# STM32H523 register map
File version: 1.2
CPU: CM33 r0p0, little endian, MPU, FPU, 4 interrupt priority bits
Registers are 32-bit, read-write, reset 0x0 unless marked. A register's access mark holds for its fields unless they carry their own. Offsets are from the block's base; [hi:lo] are bit positions; lines under a group give offsets from that group; {n}, {i} and the like mark numbered series; 'fields as' and 'values as' point back to an identical list.

## FLASH — Mustang_FLASH register block
Base 0x40022000
Same registers: FLASH_S 0x50022000
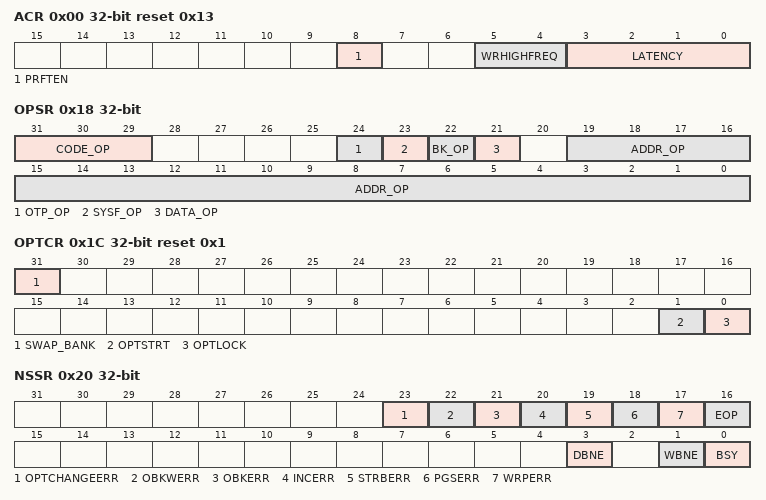
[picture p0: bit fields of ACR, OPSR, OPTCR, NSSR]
0x00 ACR reset 0x13 — FLASH access control register
  [8] PRFTEN — Prefetch enable.
  [5:4] WRHIGHFREQ — Flash signal delay
  [3:0] LATENCY — Read latency
0x04 NSKEYR wo — FLASH non-secure key register
  [31:0] NSKEY — Non-volatile memory non-secure configuration access unlock key
0x08 SECKEYR wo — FLASH secure key register
  [31:0] SECKEY — Non-volatile memory secure configuration access unlock key
0x0C OPTKEYR wo — FLASH option key register
  [31:0] OPTKEY — FLASH option bytes control access unlock key
0x10 NSOBKKEYR wo — FLASH non-secure OBK key register
  [31:0] NSOBKKEY — FLASH non-secure option bytes keys control access unlock key
0x14 SECOBKKEYR wo — FLASH secure OBK key register
  [31:0] SECOBKKEY — FLASH secure option bytes keys control access unlock key
0x18 OPSR ro reset not defined — FLASH operation status register
  [31:29] CODE_OP — Flash memory operation code
  [24] OTP_OP — OTP operation interrupted
  [23] SYSF_OP — Operation in system flash memory interrupted
  [22] BK_OP — Interrupted operation bank
  [21] DATA_OP — Flash high-cycle data area operation interrupted
  [19:0] ADDR_OP — Interrupted operation address
0x1C OPTCR reset 0x1 (reset mask 0xFFFFFFF) — FLASH option control register
  [31] SWAP_BANK ro — Bank swapping option configuration bit
  [1] OPTSTRT — Option byte start change option configuration bit
  [0] OPTLOCK — FLASH_OPTCR lock option configuration bit
0x20 NSSR ro (reset mask 0xFFFFFFF0) — FLASH non-secure status register
  [23] OPTCHANGEERR — Option byte change error flag
  [22] OBKWERR — OBK write error flag
  [21] OBKERR — OBK general error flag
  [20] INCERR — inconsistency error flag
  [19] STRBERR — strobe error flag
  [18] PGSERR — programming sequence error flag
  [17] WRPERR — write protection error flag
  [16] EOP — end of operation flag
  [3] DBNE — data buffer not empty flag
  [1] WBNE — write buffer not empty flag
  [0] BSY — busy flag
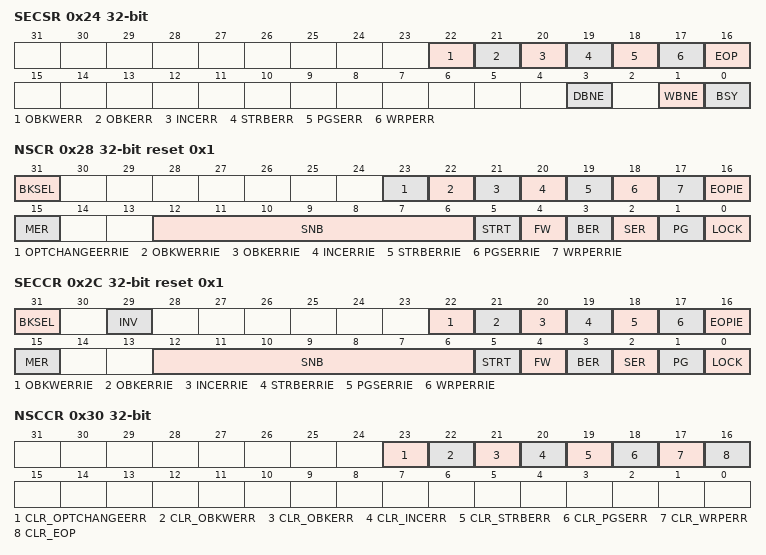
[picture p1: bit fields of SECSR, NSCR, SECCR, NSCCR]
0x24 SECSR ro (reset mask 0xFFFFFFF0) — FLASH secure status register
  [22] OBKWERR — OBK write error flag
  [21] OBKERR — OBK general error flag
  [20] INCERR — inconsistency error flag
  [19] STRBERR — strobe error flag
  [18] PGSERR — programming sequence error flag
  [17] WRPERR — write protection error flag
  [16] EOP — end of operation flag
  [3] DBNE — data buffer not empty flag
  [1] WBNE — write buffer not empty flag
  [0] BSY — busy flag
0x28 NSCR reset 0x1 — FLASH non-secure control register
  [31] BKSEL — Bank selector bit
  [23] OPTCHANGEERRIE — Option byte change error interrupt enable bit
  [22] OBKWERRIE — OBK write error interrupt enable bit
  [21] OBKERRIE — OBK general error interrupt enable bit
  [20] INCERRIE — inconsistency error interrupt enable bit
  [19] STRBERRIE — strobe error interrupt enable bit
  [18] PGSERRIE — programming sequence error interrupt enable bit
  [17] WRPERRIE — write protection error interrupt enable bit
  [16] EOPIE — end of operation interrupt control bit
  [15] MER — mass erase request
  [12:6] SNB — sector erase selection number
  [5] STRT — erase start control bit
  [4] FW — write forcing control bit
  [3] BER — erase request
  [2] SER — sector erase request
  [1] PG — programming control bit
  [0] LOCK — configuration lock bit
0x2C SECCR reset 0x1 — FLASH secure control register
  [31] BKSEL — Bank selector bit
  [29] INV — Flash memory security state invert.
  [22] OBKWERRIE — OBK write error interrupt enable bit
  [21] OBKERRIE — OBK general error interrupt enable bit
  [20] INCERRIE — inconsistency error interrupt enable bit
  [19] STRBERRIE — strobe error interrupt enable bit
  [18] PGSERRIE — programming sequence error interrupt enable bit
  [17] WRPERRIE — write protection error interrupt enable bit
  [16] EOPIE — end of operation interrupt control bit
  [15] MER — mass erase request
  [12:6] SNB — sector erase selection number
  [5] STRT — erase start control bit
  [4] FW — write forcing control bit
  [3] BER — erase request
  [2] SER — sector erase request
  [1] PG — programming control bit
  [0] LOCK — configuration lock bit
0x30 NSCCR wo — FLASH non-secure clear control register
  [23] CLR_OPTCHANGEERR — Clear the flag corresponding flag in FLASH_NSSR by writing this bit.
  [22] CLR_OBKWERR — OBKWERR flag clear bit.
  [21] CLR_OBKERR — OBKERR flag clear bit.
  [20] CLR_INCERR — INCERR flag clear bit
  [19] CLR_STRBERR — STRBERR flag clear bit
  [18] CLR_PGSERR — PGSERR flag clear bit
  [17] CLR_WRPERR — WRPERR flag clear bit
  [16] CLR_EOP — EOP flag clear bit
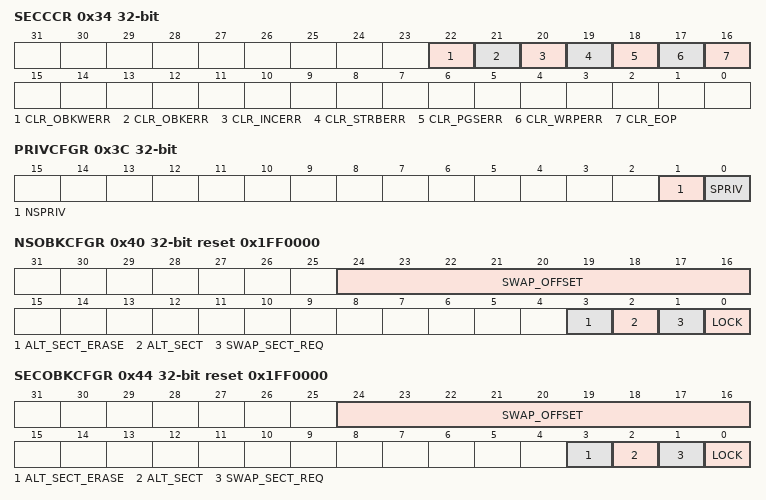
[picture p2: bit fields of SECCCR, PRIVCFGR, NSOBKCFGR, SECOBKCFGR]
0x34 SECCCR wo — FLASH secure clear control register
  [22] CLR_OBKWERR — OBKWERR flag clear bit
  [21] CLR_OBKERR — OBKWERR flag clear bit
  [20] CLR_INCERR — INCERR flag clear bit
  [19] CLR_STRBERR — STRBERR flag clear bit
  [18] CLR_PGSERR — PGSERR flag clear bit
  [17] CLR_WRPERR — WRPERR flag clear bit
  [16] CLR_EOP — EOP flag clear bit
0x3C PRIVCFGR — FLASH privilege configuration register
  [1] NSPRIV — privilege attribute for non secure registers
  [0] SPRIV — privilege attribute for secure registers
0x40 NSOBKCFGR reset 0x1FF0000 — FLASH non-secure OBK configuration register
  [24:16] SWAP_OFFSET — Key index (offset /16 bits) pointing for next swap.
  [3] ALT_SECT_ERASE — alternate sector erase bit
  [2] ALT_SECT — alternate sector bit
  [1] SWAP_SECT_REQ — OBK swap sector request bit
  [0] LOCK — OBKCFGR lock option configuration bit
0x44 SECOBKCFGR reset 0x1FF0000 — FLASH secure OBK configuration register
  [24:16] SWAP_OFFSET — key index (offset /16 bits) pointing for next swap.
  [3] ALT_SECT_ERASE — alternate sector erase bit
  [2] ALT_SECT — alternate sector bit
  [1] SWAP_SECT_REQ — OBK swap sector request bit
  [0] LOCK — OBKCFGR lock option configuration bit
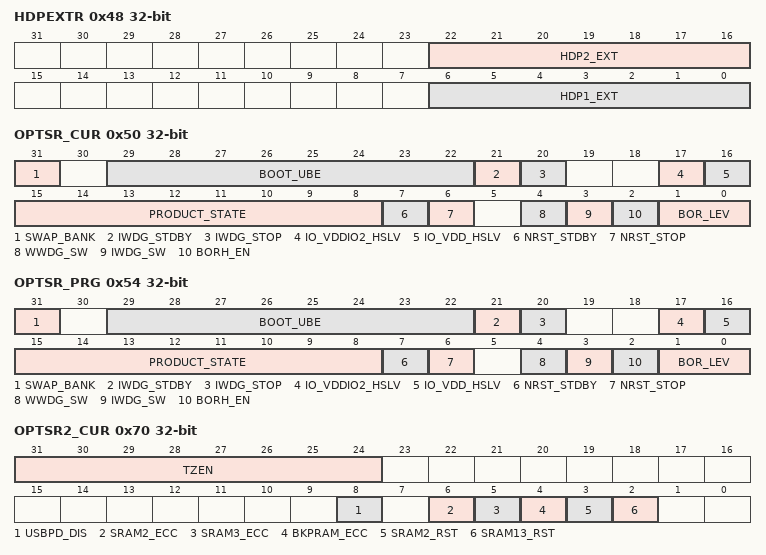
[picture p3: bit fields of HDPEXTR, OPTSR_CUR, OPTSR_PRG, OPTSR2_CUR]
0x48 HDPEXTR — FLASH HDP extension register
  [22:16] HDP2_EXT — HDP area extension in 8 Kbytes sectors in Bank2.
  [6:0] HDP1_EXT — HDP area extension in 8 Kbytes sectors in Bank1.
0x50 OPTSR_CUR ro reset not defined — FLASH option status register
  [31] SWAP_BANK — Bank swapping option status bit
  [29:22] BOOT_UBE — Available only on cryptography enabled devices.
  [21] IWDG_STDBY — IWDG Standby mode freeze option status bit
  [20] IWDG_STOP — IWDG Stop mode freeze option status bit
  [17] IO_VDDIO2_HSLV — High-speed IO at low Vless thansub>DDIO2less than/sub> voltage configuration bit.
  [16] IO_VDD_HSLV — High-speed IO at low Vless thansub>DDless than/sub> voltage configuration bit.
  [15:8] PRODUCT_STATE — Life state code (based on Hamming 8,4).
  [7] NRST_STDBY — Core domain Standby entry reset option status bit
  [6] NRST_STOP — Core domain Stop entry reset option status bit
  [4] WWDG_SW — WWDG control mode option status bit
  [3] IWDG_SW — IWDG control mode option status bit
  [2] BORH_EN — Brownout high enable
  [1:0] BOR_LEV — Brownout level option status bit
0x54 OPTSR_PRG reset not defined — FLASH option status register
  [31] SWAP_BANK — Bank swapping option configuration bit
  [29:22] BOOT_UBE — Available only on cryptography enabled devices.
  [21] IWDG_STDBY — IWDG Standby mode freeze option status bit
  [20] IWDG_STOP — IWDG Stop mode freeze option status bit
  [17] IO_VDDIO2_HSLV — High-speed IO at low Vless thansub>DDIO2less than/sub> voltage configuration bit.
  [16] IO_VDD_HSLV — High-speed IO at low VDD voltage configuration bit.
  [15:8] PRODUCT_STATE — Life state code (based on Hamming 8,4).
  [7] NRST_STDBY — Core domain Standby entry reset option configuration bit
  [6] NRST_STOP — Core domain Stop entry reset option configuration bit
  [4] WWDG_SW — WWDG control mode option configuration bit
  [3] IWDG_SW — IWDG control mode option configuration bit
  [2] BORH_EN — Brownout high enable configuration bit
  [1:0] BOR_LEV — Brownout level option configuration bit
0x60 NSEPOCHR_CUR ro reset not defined — FLASH non-secure EPOCH register
  [23:0] NS_EPOCH — Non-volatile non-secure EPOCH counter
0x68 SECEPOCHR_CUR ro reset not defined — FLASH secure EPOCH register
  [23:0] SEC_EPOCH — Non-volatile secure EPOCH counter
0x70 OPTSR2_CUR ro reset not defined — FLASH option status register 2
  [31:24] TZEN — TrustZone enable configuration bits
  [8] USBPD_DIS — USB power delivery configuration option bit
  [6] SRAM2_ECC — SRAM2 ECC detection and correction disable
  [5] SRAM3_ECC — SRAM3 ECC detection and correction disable
  [4] BKPRAM_ECC — Backup RAM ECC detection and correction disable
  [3] SRAM2_RST — SRAM2 erase when system reset
  [2] SRAM13_RST — SRAM1 and SRAM3 erase upon system reset
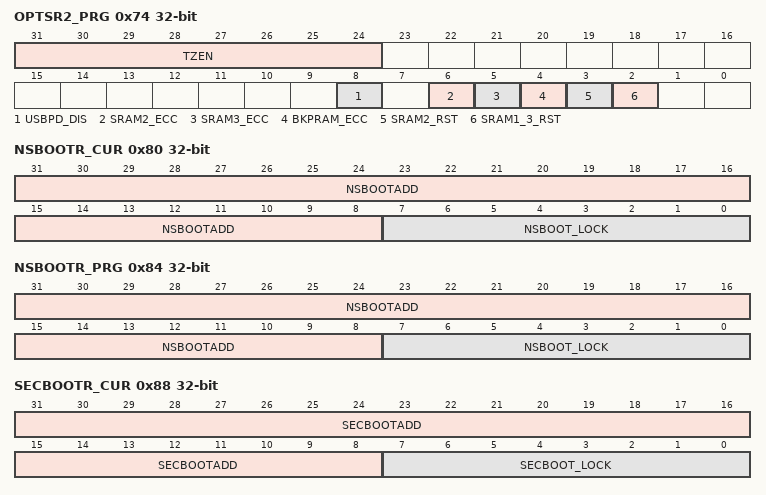
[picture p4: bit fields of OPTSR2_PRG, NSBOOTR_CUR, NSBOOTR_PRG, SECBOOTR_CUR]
0x74 OPTSR2_PRG reset not defined — FLASH option status register 2
  [31:24] TZEN — TrustZone enable configuration bits
  [8] USBPD_DIS — USB power delivery configuration option bit
  [6] SRAM2_ECC — SRAM2 ECC detection and correction disable
  [5] SRAM3_ECC — SRAM3 ECC detection and correction disable
  [4] BKPRAM_ECC — Backup RAM ECC detection and correction disable
  [3] SRAM2_RST — SRAM2 erase when system reset
  [2] SRAM1_3_RST — SRAM1 and SRAM3 erase upon system reset
0x80 NSBOOTR_CUR ro reset not defined — FLASH non-secure boot register
  [31:8] NSBOOTADD — Non secure unique boot entry address
  [7:0] NSBOOT_LOCK — Field locking the values of SWAP_BANK, and NSBOOTADD settings.
0x84 NSBOOTR_PRG reset not defined — FLASH non-secure boot register
  [31:8] NSBOOTADD — Non secure unique boot entry address
  [7:0] NSBOOT_LOCK — Field locking the values of SWAP_ BANK, and NSBOOTADD settings.
0x88 SECBOOTR_CUR ro reset not defined — FLASH secure boot register
  [31:8] SECBOOTADD — Unique boot entry secure address
  [7:0] SECBOOT_LOCK — Field locking the values of UBE, SWAP_BANK, and SECBOOTADD settings.
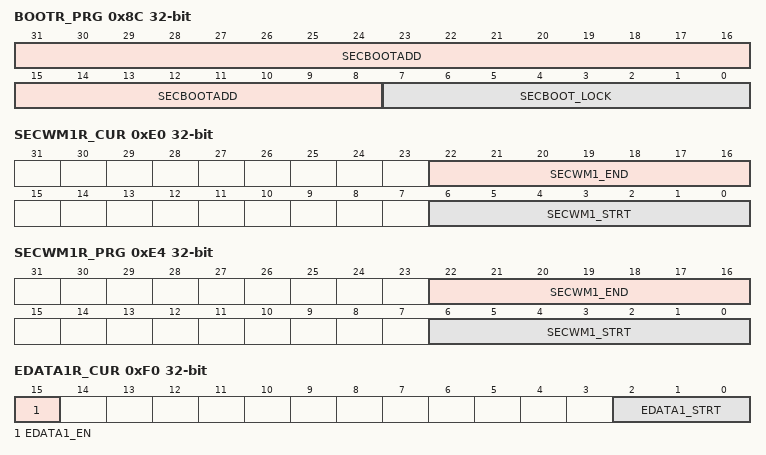
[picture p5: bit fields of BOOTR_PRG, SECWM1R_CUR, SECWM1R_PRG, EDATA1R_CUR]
0x8C BOOTR_PRG reset not defined — FLASH secure boot register
  [31:8] SECBOOTADD — Secure unique boot entry address.
  [7:0] SECBOOT_LOCK — Field locking the values of UBE, SWAP_ BANK, and SECBOOTADD setting.
0x90 OTPBLR_CUR ro reset not defined — FLASH non-secure OTP block lock
  [31:0] LOCKBL — OTP block lock
0x94 OTPBLR_PRG reset not defined — FLASH non-secure OTP block lock
  [31:0] LOCKBL — OTP block lock
{0x9C+4i} SECBB1R{i} (i=1..4) — FLASH secure block based register for Bank1
  [31:0] SECBB1 — Secure/non-secure 8 Kbytes flash Bank1 sector attributes
{0xBC+4i} PRIVBB1R{i} (i=1..4) — FLASH privilege block based register for Bank1
  [31:0] PRIVBB1 — Privileged/unprivileged 8-Kbyte flash Bank1 sector attribute
0xE0 SECWM1R_CUR ro (reset mask 0xFF00FF00) — FLASH security watermark for Bank1
  [22:16] SECWM1_END — Bank1 security WM area 1 end sector
  [6:0] SECWM1_STRT — Bank1 security WM area 1 start sector
0xE4 SECWM1R_PRG (reset mask 0xFF00FF00) — FLASH security watermark for Bank1
  fields as SECWM1R_CUR
0xE8 WRP1R_CUR ro reset not defined — FLASH write sector group protection for Bank1
  [31:0] WRPSG1 — Bank1 sector group protection option status byte
0xEC WRP1R_PRG reset not defined — FLASH write sector group protection for Bank1
  [31:0] WRPSG1 — Bank1 sector group protection option status byte
0xF0 EDATA1R_CUR ro reset not defined — FLASH data sector configuration Bank1
  [15] EDATA1_EN — Bank1 flash high-cycle data enable
  [2:0] EDATA1_STRT — EDATA1_STRT contains the start sectors of the flash high-cycle data area in Bank1 There is no hardware effect to those bits.
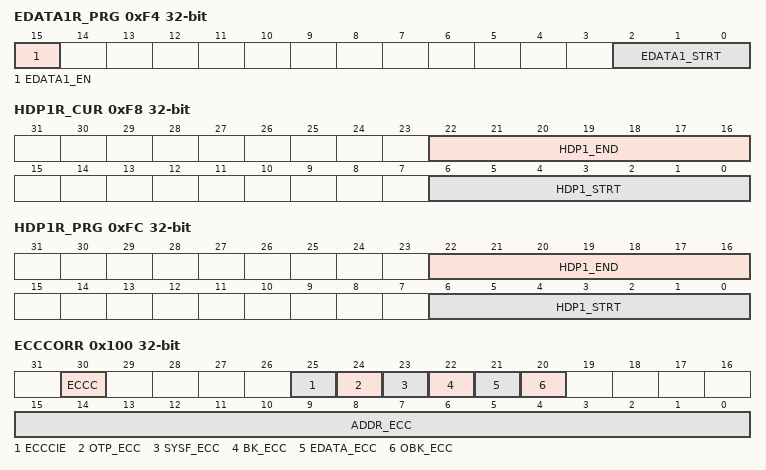
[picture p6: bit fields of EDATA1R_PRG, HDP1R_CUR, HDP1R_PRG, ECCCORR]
0xF4 EDATA1R_PRG reset not defined — FLASH data sector configuration Bank1
  fields as EDATA1R_CUR
0xF8 HDP1R_CUR ro reset not defined — FLASH HDP Bank1 configuration
  [22:16] HDP1_END — HDPL barrier end set in number of 8-Kbyte sectors
  [6:0] HDP1_STRT — HDPL barrier start set in number of 8-Kbyte sectors
0xFC HDP1R_PRG reset not defined — FLASH HDP Bank1 configuration
  fields as HDP1R_CUR
0x100 ECCCORR — FLASH ECC correction register
  [30] ECCC — ECC correction set by hardware when single ECC error has been detected and corrected.
  [25] ECCCIE — ECC single correction error interrupt enable bit
  [24] OTP_ECC ro — OTP ECC error bit
  [23] SYSF_ECC ro — ECC fail for corrected ECC error in system flash memory
  [22] BK_ECC ro — ECC fail bank for corrected ECC error
  [21] EDATA_ECC ro — ECC fail for corrected ECC error in flash high-cycle data area
  [20] OBK_ECC ro — Single ECC error corrected in flash OB Keys storage area.
  [15:0] ADDR_ECC ro — ECC error address
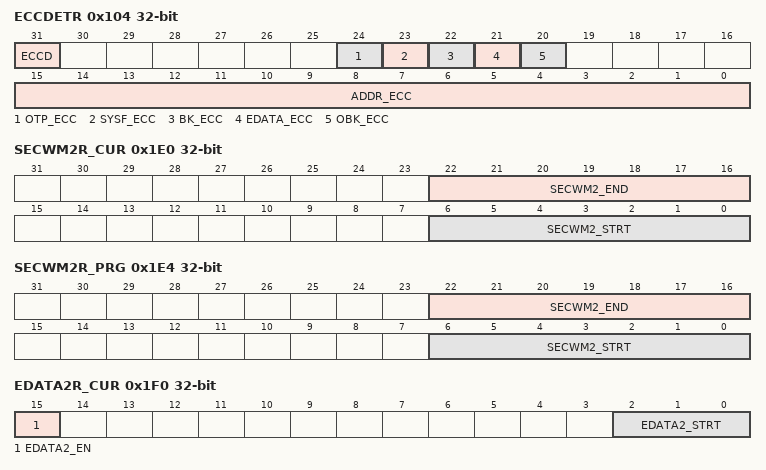
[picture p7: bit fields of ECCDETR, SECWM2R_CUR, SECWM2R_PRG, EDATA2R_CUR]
0x104 ECCDETR — FLASH ECC detection register
  [31] ECCD — ECC detection
  [24] OTP_ECC ro — OTP ECC error bit
  [23] SYSF_ECC ro — ECC fail for double ECC error in system flash memory
  [22] BK_ECC ro — ECC fail bank for double ECC error
  [21] EDATA_ECC ro — ECC fail double ECC error in flash high-cycle data area
  [20] OBK_ECC ro — ECC fail double ECC error in flash OB Keys storage area.
  [15:0] ADDR_ECC ro — ECC error address
0x108 ECCDR ro — FLASH ECC data
  [15:0] DATA_ECC — ECC error data
{0x19C+4i} SECBB2R{i} (i=1..4) — FLASH secure block-based register for Bank2
  [31:0] SECBB2 — Secure/non-secure flash Bank2 sector attribute
{0x1BC+4i} PRIVBB2R{i} (i=1..4) — FLASH privilege block-based register for Bank2
  [31:0] PRIVBB2 — Privileged / non-privileged 8-Kbyte flash Bank2 sector attribute
0x1E0 SECWM2R_CUR ro (reset mask 0xFF00FF00) — FLASH security watermark for Bank2
  [22:16] SECWM2_END — Bank2 security WM end sector
  [6:0] SECWM2_STRT — Bank2 security WM area start sector
0x1E4 SECWM2R_PRG (reset mask 0xFF00FF00) — FLASH security watermark for Bank2
  [22:16] SECWM2_END — Bank2 security WM area end sector
  [6:0] SECWM2_STRT — Bank2 security WM area start sector
0x1E8 WRP2R_CUR ro reset not defined — FLASH write sector group protection for Bank2
  [31:0] WRPSG2 — Bank2 sector group protection option status byte
0x1EC WRP2R_PRG reset not defined — FLASH write sector group protection for Bank2
  [31:0] WRPSG2 — Bank2 sector group protection option status byte
0x1F0 EDATA2R_CUR ro reset not defined — FLASH data sectors configuration Bank2
  [15] EDATA2_EN — Bank2 flash high-cycle data enable
  [2:0] EDATA2_STRT — EDATA2_STRT contains the start sectors of the flash high-cycle data area in Bank2 There is no hardware effect to those bits.
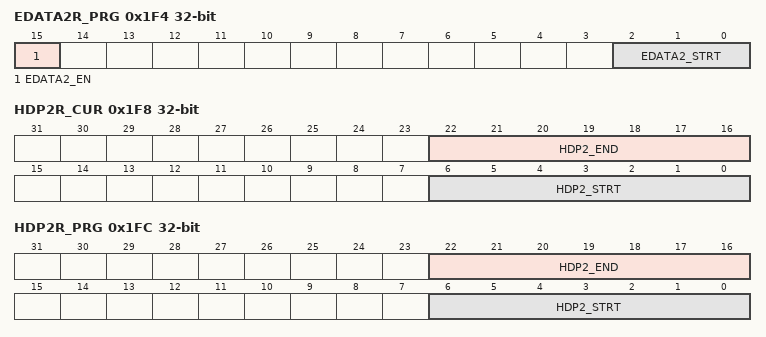
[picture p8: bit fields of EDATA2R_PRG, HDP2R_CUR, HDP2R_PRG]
0x1F4 EDATA2R_PRG reset not defined — FLASH data sector configuration Bank2
  fields as EDATA2R_CUR
0x1F8 HDP2R_CUR ro reset not defined — FLASH HDP Bank2 configuration
  [22:16] HDP2_END — HDPL barrier end set in number of 8-Kbyte sectors
  [6:0] HDP2_STRT — HDPL barrier start set in number of 8-Kbyte sectors
0x1FC HDP2R_PRG reset not defined — FLASH HDP Bank2 configuration
  fields as HDP2R_CUR
